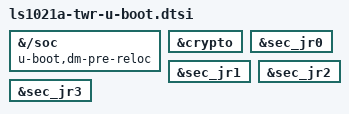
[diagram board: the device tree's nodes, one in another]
// SPDX-License-Identifier: GPL-2.0-or-later
/*
 * Copyright 2022 NXP
 */

&{/soc} {
	u-boot,dm-spl;
	u-boot,dm-pre-reloc;
};

&crypto {
	u-boot,dm-spl;
};

&sec_jr0 {
	u-boot,dm-spl;
};

&sec_jr1 {
	u-boot,dm-spl;
};

&sec_jr2 {
	u-boot,dm-spl;
};

&sec_jr3 {
	u-boot,dm-spl;
};
